# ECD3_BFSW_ICONT register map
Vendor: Texas Instruments
Peripheral module from a debugger description file (folder omap5430_ES2_PUBLIC).
Registers are 32-bit, access per field, reset 0x0 unless marked. A register's access mark holds for its fields unless they carry their own. Offsets are as the file gives them; lines under a group give offsets from that group; [hi:lo] are bit positions; {n}, {i} and the like mark numbered series; 'fields as' and 'values as' point back to an identical list; <NAME> marks a mode.

## ECD3_BFSW_ICONT
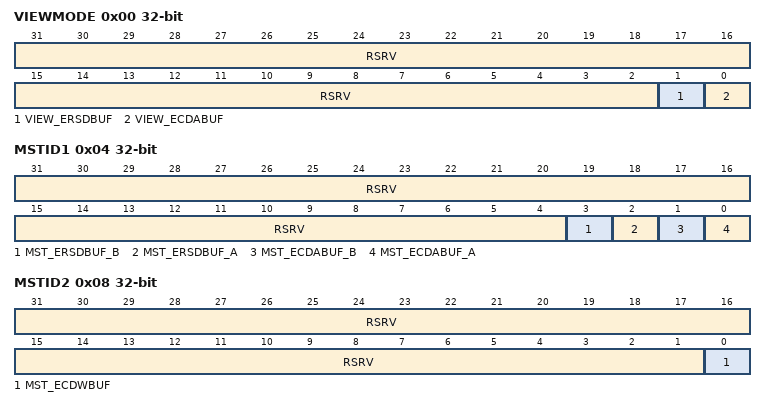
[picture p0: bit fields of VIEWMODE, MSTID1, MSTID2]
0x00 VIEWMODE — View Mode Register. It selects full-view mode or ping-pong view mode.
  [31:2] RSRV ro — Reserved. 0 will be returned at Read, and Write will be ignored.
  [1] VIEW_ERSDBUF rw — View mode selection for ersdbuf. 0x0: Full view mode is selected. 0x1: Ping-pong view mode is selected.
  [0] VIEW_ECDABUF rw — View mode selection for ecdabuf. 0x0: Full view mode is selected. 0x1: Ping-pong view mode is selected.
0x04 MSTID1 access not given — Master ID 1 Register Select master between HWA and DMA bus. This register is used in both full view and ping-pong view mode. This register is for buffers which has two physical memories. This register is affected by direct_switch_pi input port.
  [31:4] RSRV — Reserved. 0 will be returned at Read, and Write will be ignored. (access RB)
  [3] MST_ERSDBUF_B rw — Master selection for ersdbuf B. This bit is used in only ping-pong view mode. 0x0: Buffer B is assigned to DMA 0x1: Buffer B is assigned to HWA. This bit has no effect in full view mode. If direct_switch_pi is high, the value of this bit is inverted.
  [2] MST_ERSDBUF_A — Master selection for ersdbuf A. This bit is used in both full view and ping-pong view mode. In full view mode: 0x0: In full view mode, both buffer A and B are assigned to DMA 0x1: Both buffer A and B are assigned to HWA. In ping-pong view mode: 0x0: Buffer A is assigned to DMA 0x1: Buffer A is assigned to HWA. Buffer B is not affected in ping-pong view mode. If direct_switch_pi is high, the value of this bit is inverted. (access RWB)
  [1] MST_ECDABUF_B rw — Master selection for ecdabuf B. This bit is used in only ping-pong view mode. 0x0: Buffer B is assigned to DMA 0x1: Buffer B is assigned to HWA. This bit has no effect in full view mode. If direct_switch_pi is high, the value of this bit is inverted.
  [0] MST_ECDABUF_A rw — Master selection for ecdabuf A. This bit is used in both full view and ping-pong view mode. In full view mode: 0x0: Both buffer A and B are assigned to DMA 0x1: Both buffer A and B are assigned to HWA. In ping-pong view mode: 0x0: Buffer A is assigned to DMA 0x1: Buffer A is assigned to HWA. Buffer B is not affected in ping-pong view mode. If direct_switch_pi is high, the value of this bit is inverted.
0x08 MSTID2 — Master ID 1 Register Select master between HWA and DMA bus. This register is for buffers which has only one physical memory. This register is NOT affected by direct_switch_pi input port.
  [31:1] RSRV ro — Reserved. 0 will be returned at Read, and Write will be ignored.
  [0] MST_ECDWBUF rw — Master selection for ecdwbuf. 0x0: The buffer is assigned to DMA 0x1:The buffer is assigned to HWA.
